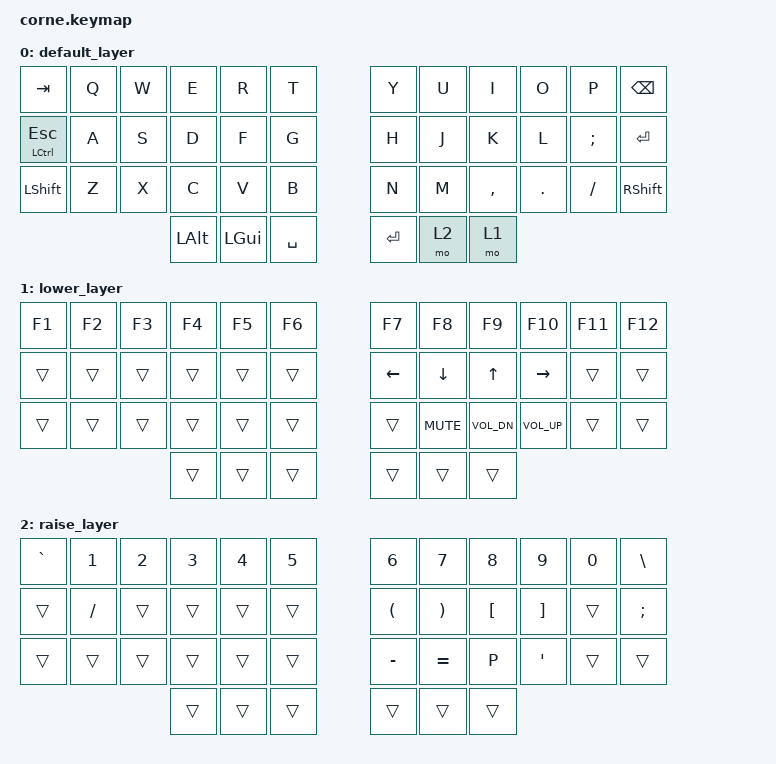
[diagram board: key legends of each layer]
/*
 * Copyright (c) 2020 The ZMK Contributors
 *
 * SPDX-License-Identifier: MIT
 */

#include <behaviors.dtsi>
#include <dt-bindings/zmk/keys.h>
#include <dt-bindings/zmk/bt.h>

/ {
        keymap {
                compatible = "zmk,keymap";

                default_layer {
// -----------------------------------------------------------------------------------------
// |  TAB      |  Q  |  W  |  E   |  R   |  T  |   |  Y  |  U   |  I   |  O   |  P   | BKSP |
// |  ESC/CTRL |  A  |  S  |  D   |  F   |  G  |   |  H  |  J   |  K   |  L   |  ;   | ENT  |
// | SHFT      |  Z  |  X  |  C   |  V   |  B  |   |  N  |  M   |  <,  |  >.  |  /?  | SHFT  |
//                         | LALT | LGUI | SPC |   | LWR | RSE  | ALT  |

                        bindings = <
   &kp TAB       &kp Q    &kp W    &kp E      &kp R    &kp T    &kp Y    &kp U     &kp I    &kp O    &kp P    &kp BSPC
   &mt LCTRL ESC &kp A    &kp S    &kp D      &kp F    &kp G    &kp H    &kp J     &kp K    &kp L    &kp SEMI &kp RET
   &kp LSHFT     &kp Z    &kp X    &kp C      &kp V    &kp B    &kp N    &kp M     &kp COMMA&kp DOT  &kp FSLH &kp RSHFT
                 &kp LALT &kp LGUI &kp SPACE           &kp RET    &mo 2    &mo 1
                        >;
                };
                lower_layer {
// -----------------------------------------------------------------------------------------
// | F1 | F2 | F3 | F4 | F5 | F6 |   |  F7  |  F8 |  F9   | F10  |  F11  |  F12 |
// |    |    |    |    |    |    |   | LFT  | DWN |  UP   | RGT  |       |      |
// |    |    |    |    |    |    |   |      | MUTE|  VOL- | VOL+ |       |      |
//                     |    |    |   |      |     |       |      |
                        bindings = <
   &kp F1     &kp F2      &kp F3      &kp F4      &kp F5      &kp F6       &kp F7   &kp F8     &kp F9       &kp F10       &kp F11 &kp F12
   &trans     &trans      &trans      &trans      &trans      &trans       &kp LEFT &kp DOWN   &kp UP       &kp RIGHT     &trans  &trans
   &trans     &trans      &trans      &trans      &trans      &trans       &trans   &kp K_MUTE &kp K_VOL_DN &kp K_VOL_UP  &trans  &trans
                          &trans      &trans      &trans      &trans       &trans   &trans
                        >;
                };

                raise_layer {
// -----------------------------------------------------------------------------------------
// |  `~  |  1!  |  2@  |  3#  |  4$  |  5%  |   |  6^   |  7&  |  8*   |  9(   |  0)  |  |\  |
// |      |  ?/  |      |      |      |      |   |  (    |  )   |  {[   |  ]}   |      |  :;  |
// |      |      |      |      |      |      |   |  _-   |  +=  |  :;   |  "'   |      |      |
//                      |      |      |      |   |       |      |       |
                        bindings = <
   &kp GRAVE  &kp N1   &kp N2   &kp N3   &kp N4   &kp N5      &kp N6     &kp N7      &kp N8    &kp N9    &kp N0   &kp BSLH
   &trans     &kp FSLH &trans   &trans   &trans   &trans      &kp LPAR   &kp RPAR    &kp LBKT  &kp RBKT  &trans   &kp SEMI
   &trans     &trans   &trans   &trans   &trans   &trans      &kp MINUS  &kp EQUAL   &kp P  &kp APOS  &trans   &trans
                                &trans   &trans   &trans      &trans     &trans      &trans
                        >;
                };
        };
};
